# STM32H7A3 register map
File version: 3.4
CPU: CM7 r0p1, little endian, MPU, FPU, 4 interrupt priority bits
Registers are 32-bit, read-write, reset 0x0 unless marked. A register's access mark holds for its fields unless they carry their own. Offsets are from the block's base; [hi:lo] are bit positions; {n}, {i} and the like mark numbered series.

## DBGMCU — Microcontroller Debug Unit
Base 0x5C001000
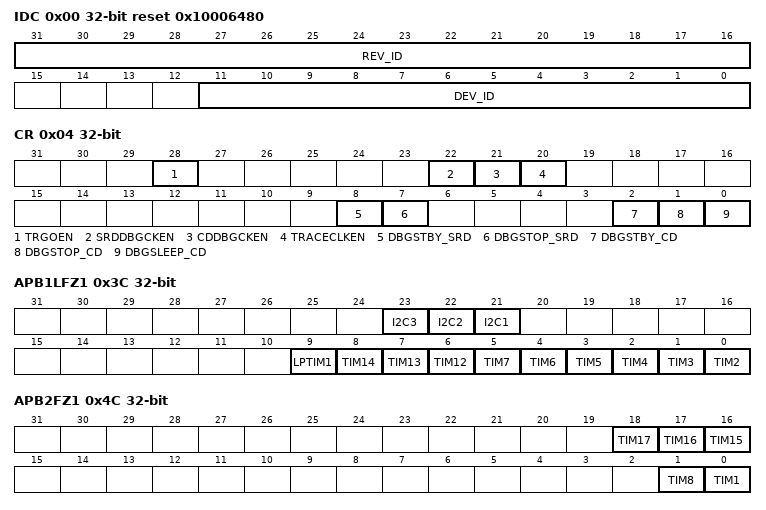
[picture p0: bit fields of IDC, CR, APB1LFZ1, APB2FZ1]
0x00 IDC ro reset 0x10006480 — DBGMCU Identity Code Register
  [31:16] REV_ID — Revision
  [11:0] DEV_ID — Device ID
0x04 CR — DBGMCU Configuration Register
  [28] TRGOEN — External trigger output enable
  [22] SRDDBGCKEN — SmartRun domain debug clock enable
  [21] CDDBGCKEN — CPU domain debug clock enable
  [20] TRACECLKEN — Trace port clock enable
  [8] DBGSTBY_SRD — debug in SmartRun domain Standby mode
  [7] DBGSTOP_SRD — debug in SmartRun domain Stop mode
  [2] DBGSTBY_CD — Allow D1 domain debug in Standby mode
  [1] DBGSTOP_CD — Allow D1 domain debug in Stop mode
  [0] DBGSLEEP_CD — Allow D1 domain debug in Sleep mode
0x34 APB3FZ1 — DBGMCU APB3 peripheral freeze register
  [6] WWDG — WWDG stop in debug
0x3C APB1LFZ1 — DBGMCU APB1L peripheral freeze register
  [23] I2C3 — I2C3 SMBUS timeout stop in debug
  [22] I2C2 — I2C2 SMBUS timeout stop in debug
  [21] I2C1 — I2C1 SMBUS timeout stop in debug
  [9] LPTIM1 — LPTIM1 stop in debug
  [8] TIM14 — TIM14 stop in debug
  [7] TIM13 — TIM13 stop in debug
  [6] TIM12 — TIM12 stop in debug
  [n-2] TIM{n} (n=2..7) — TIM{n} stop in debug
0x4C APB2FZ1 — DBGMCU APB2 peripheral freeze register
  [18] TIM17 — TIM17 stop in debug
  [17] TIM16 — TIM16 stop in debug
  [16] TIM15 — TIM15 stop in debug
  [1] TIM8 — TIM8 stop in debug
  [0] TIM1 — TIM1 stop in debug
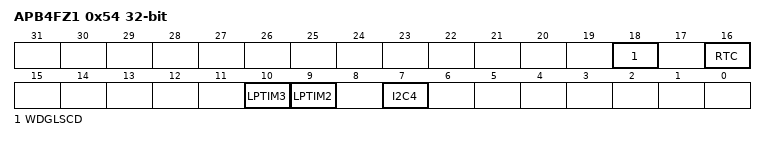
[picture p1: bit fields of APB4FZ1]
0x54 APB4FZ1 — DBGMCU APB4 peripheral freeze register
  [18] WDGLSCD — LS watchdog for CPU domain stop in debug
  [16] RTC — RTC stop in debug
  [10] LPTIM3 — LPTIM3 stop in debug
  [9] LPTIM2 — LPTIM2 stop in debug
  [7] I2C4 — I2C4 SMBUS timeout stop in debug

## DELAY_Block_SDMMC1
Base 0x52008000
Same registers: DELAY_Block_SDMMC2 0x48022800, Delay_Block_OCTOSPI1 0x52006000, Delay_Block_OCTOSPI2 0x5200B000
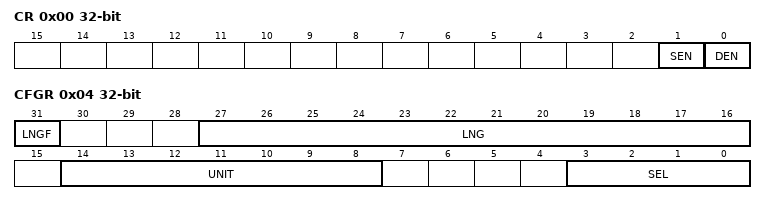
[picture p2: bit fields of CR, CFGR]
0x00 CR — DLYB control register
  [1] SEN — Sampler length enable bit
  [0] DEN — Delay block enable bit
0x04 CFGR — DLYB configuration register
  [31] LNGF — Length valid flag
  [27:16] LNG — Delay line length value
  [14:8] UNIT — Delay Defines the delay of a Unit delay cell
  [3:0] SEL — Select the phase for the Output clock

## HSEM
Base 0x48020800
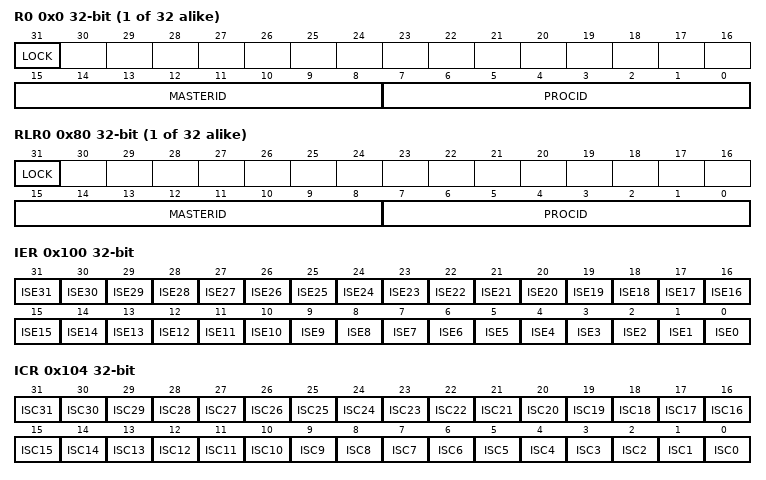
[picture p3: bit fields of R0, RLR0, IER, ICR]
{0x0+4i} R{i} (i=0..31) — HSEM register HSEM_R{i}
  [31] LOCK — Lock indication
    on read: 0=Free (Semaphore is free); 1=Locked (Semaphore is locked) | on write: 0=Free semaphore; 1=TryLock (Try to lock semaphore)
  [15:8] MASTERID range 0..15 — Semaphore MasterID
  [7:0] PROCID — Semaphore ProcessID
{0x80+4i} RLR{i} (i=0..31) ro — Semaphore {i} read lock register
  [31] LOCK — Lock indication
    0=Free (Semaphore is free); 1=Locked (Semaphore is locked)
  [15:8] MASTERID range 0..15 — Semaphore MasterID
  [7:0] PROCID — Semaphore ProcessID
0x100 IER — HSEM Interrupt enable register
  [n] ISE{n} (n=0..31) — Interrupt semaphore {n} enable bit
    0=Disabled (Interrupt generation disabled); 1=Enabled (Interrupt generation enabled)
0x104 ICR — HSEM Interrupt clear register
  [n] ISC{n} (n=0..31) — Interrupt semaphore {n} clear bit
    on read: 0=NoEffect (Always reads 0) | on write: 0=NoEffect (Interrupt semaphore x status ISFx and masked status MISFx not affected); 1=Clear (Interrupt semaphore x status ISFx and masked status MISFx cleared)
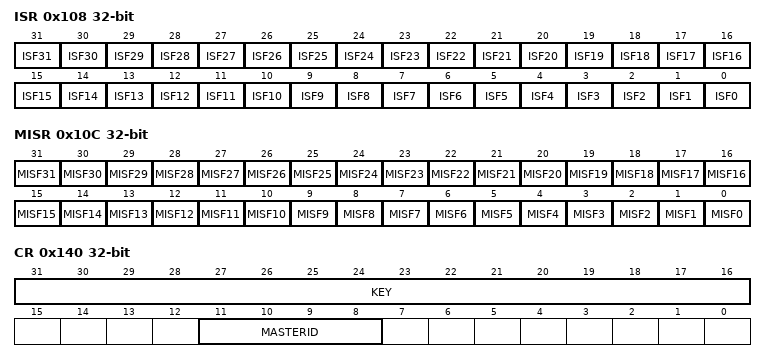
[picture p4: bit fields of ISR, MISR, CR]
0x108 ISR ro — HSEM Interrupt status register
  [n] ISF{n} (n=0..31) — Interrupt semaphore {n} status bit before enable (mask)
    0=NotPending (No interrupt pending); 1=Pending (Interrupt pending)
0x10C MISR ro — HSEM Masked interrupt status register
  [n] MISF{n} (n=0..31) — Masked interrupt semaphore {n} status bit after enable (mask)
    0=NotPending (No interrupt pending after masking); 1=Pending (Interrupt pending after masking)
0x140 CR — HSEM Clear register
  [31:16] KEY — Semaphore clear Key
  [11:8] MASTERID — MasterID of semaphores to be cleared
0x144 KEYR — HSEM Interrupt clear register
  [31:16] KEY — Semaphore Clear Key
